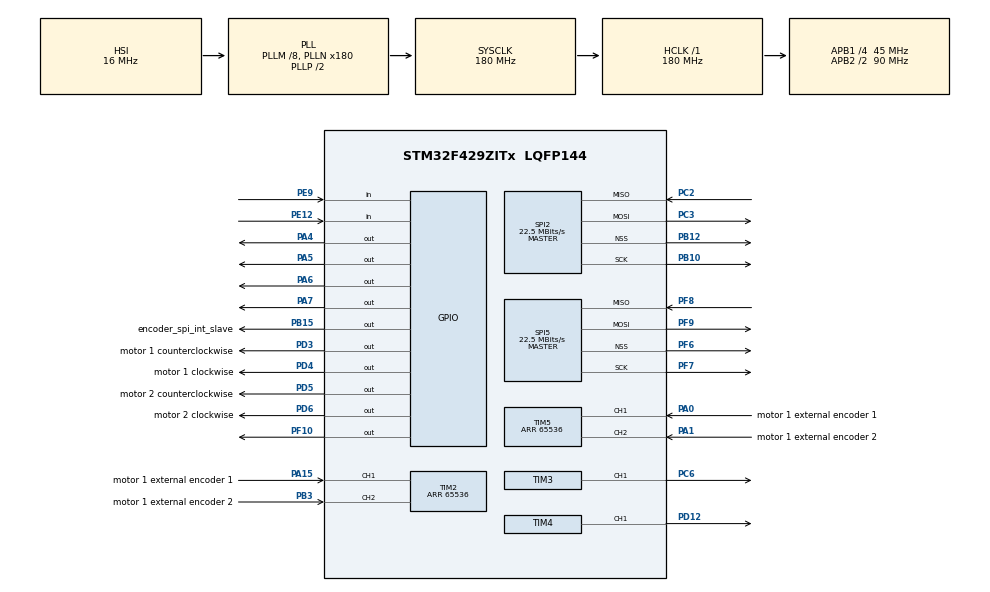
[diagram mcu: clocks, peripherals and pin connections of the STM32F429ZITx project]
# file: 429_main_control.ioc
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Mcu.Family=STM32F4
Mcu.Name=STM32F429ZITx
Mcu.Package=LQFP144
NVIC.PriorityGroup=NVIC_PRIORITYGROUP_3
NVIC.TIM1_BRK_TIM9_IRQn=true\:1\:1\:true\:false\:true\:true
NVIC.TIM1_UP_TIM10_IRQn=true\:0\:0\:false\:false\:true\:true
NVIC.TIM8_UP_TIM13_IRQn=true\:1\:0\:true\:false\:true\:true
PA0/WKUP.GPIO_Label=motor 1 external encoder 1
PA0/WKUP.GPIO_PuPd=GPIO_PULLUP
PA0/WKUP.Signal=S_TIM5_CH1
PA1.GPIO_Label=motor 1 external encoder 2
PA1.GPIO_PuPd=GPIO_PULLUP
PA1.Signal=S_TIM5_CH2
PA15.GPIO_Label=motor 1 external encoder 1
PA15.GPIO_PuPd=GPIO_PULLUP
PA15.Signal=S_TIM2_CH1_ETR
PA4.GPIO_PuPd=GPIO_PULLDOWN
PA4.GPIO_Speed=GPIO_SPEED_FREQ_VERY_HIGH
PA4.PinState=GPIO_PIN_RESET
PA4.Signal=GPIO_Output
PA5.GPIO_PuPd=GPIO_PULLDOWN
PA5.GPIO_Speed=GPIO_SPEED_FREQ_VERY_HIGH
PA5.Signal=GPIO_Output
PA6.GPIO_PuPd=GPIO_PULLDOWN
PA6.GPIO_Speed=GPIO_SPEED_FREQ_VERY_HIGH
PA6.Signal=GPIO_Output
PA7.GPIO_PuPd=GPIO_PULLDOWN
PA7.GPIO_Speed=GPIO_SPEED_FREQ_VERY_HIGH
PA7.Signal=GPIO_Output
PB10.Mode=Full_Duplex_Master
PB10.Signal=SPI2_SCK
PB12.Mode=NSS_Signal_Hard_Output
PB12.Signal=SPI2_NSS
PB15.GPIO_Label=encoder_spi_int_slave
PB15.GPIO_PuPd=GPIO_PULLUP
PB15.GPIO_Speed=GPIO_SPEED_FREQ_VERY_HIGH
PB15.PinState=GPIO_PIN_SET
PB15.Signal=GPIO_Output
PB3.GPIO_Label=motor 1 external encoder 2
PB3.GPIO_PuPd=GPIO_PULLUP
PB3.Signal=S_TIM2_CH2
PC2.Mode=Full_Duplex_Master
PC2.Signal=SPI2_MISO
PC3.Mode=Full_Duplex_Master
PC3.Signal=SPI2_MOSI
PC6.Signal=S_TIM3_CH1
PD12.Signal=S_TIM4_CH1
PD3.GPIO_Label=motor 1 counterclockwise
PD3.GPIO_PuPd=GPIO_PULLDOWN
PD3.GPIO_Speed=GPIO_SPEED_FREQ_VERY_HIGH
PD3.Signal=GPIO_Output
PD4.GPIO_Label=motor 1 clockwise
PD4.GPIO_ModeDefaultOutputPP=GPIO_MODE_OUTPUT_PP
PD4.GPIO_PuPd=GPIO_PULLDOWN
PD4.GPIO_Speed=GPIO_SPEED_FREQ_VERY_HIGH
PD4.Signal=GPIO_Output
PD5.GPIO_Label=motor 2 counterclockwise
PD5.GPIO_PuPd=GPIO_PULLDOWN
PD5.GPIO_Speed=GPIO_SPEED_FREQ_VERY_HIGH
PD5.Signal=GPIO_Output
PD6.GPIO_Label=motor 2 clockwise
PD6.GPIO_PuPd=GPIO_PULLDOWN
PD6.GPIO_Speed=GPIO_SPEED_FREQ_VERY_HIGH
PD6.Signal=GPIO_Output
PE12.GPIO_PuPd=GPIO_PULLUP
PE12.Signal=GPIO_Input
PE9.GPIO_PuPd=GPIO_PULLUP
PE9.Signal=GPIO_Input
PF10.Signal=GPIO_Output
PF6.Mode=NSS_Signal_Hard_Output
PF6.Signal=SPI5_NSS
PF7.Mode=Full_Duplex_Master
PF7.Signal=SPI5_SCK
PF8.Mode=Full_Duplex_Master
PF8.Signal=SPI5_MISO
PF9.Mode=Full_Duplex_Master
PF9.Signal=SPI5_MOSI
PH0/OSC_IN.Mode=HSE-External-Oscillator
PH0/OSC_IN.Signal=RCC_OSC_IN
PH1/OSC_OUT.Mode=HSE-External-Oscillator
PH1/OSC_OUT.Signal=RCC_OSC_OUT
ProjectManager.HeapSize=0x200
ProjectManager.StackSize=0x400
ProjectManager.TargetToolchain=MDK-ARM V5
RCC.48MHZClocksFreq_Value=90000000
RCC.AHBFreq_Value=180000000
RCC.APB1CLKDivider=RCC_HCLK_DIV4
RCC.APB1Freq_Value=45000000
RCC.APB1TimFreq_Value=90000000
RCC.APB2CLKDivider=RCC_HCLK_DIV2
RCC.APB2Freq_Value=90000000
RCC.APB2TimFreq_Value=180000000
RCC.CortexFreq_Value=180000000
RCC.HCLKFreq_Value=180000000
RCC.HSE_VALUE=8000000
RCC.HSI_VALUE=16000000
RCC.LSE_VALUE=32768
RCC.PLLM=8
RCC.PLLN=180
RCC.SYSCLKFreq_VALUE=180000000
RCC.SYSCLKSource=RCC_SYSCLKSOURCE_PLLCLK
RCC.VCOOutputFreq_Value=360000000
SH.S_TIM2_CH1_ETR.0=TIM2_CH1,Encoder_Interface
SH.S_TIM2_CH2.0=TIM2_CH2,Encoder_Interface
SH.S_TIM3_CH1.0=TIM3_CH1,PWM Generation1 CH1
SH.S_TIM4_CH1.0=TIM4_CH1,PWM Generation1 CH1
SH.S_TIM5_CH1.0=TIM5_CH1,Encoder_Interface
SH.S_TIM5_CH2.0=TIM5_CH2,Encoder_Interface
SPI2.BaudRatePrescaler=SPI_BAUDRATEPRESCALER_2
SPI2.CalculateBaudRate=22.5 MBits/s
SPI2.Direction=SPI_DIRECTION_2LINES
SPI2.Mode=SPI_MODE_MASTER
SPI2.VirtualNSS=VM_NSSHARD
SPI2.VirtualType=VM_MASTER
SPI5.BaudRatePrescaler=SPI_BAUDRATEPRESCALER_4
SPI5.CalculateBaudRate=22.5 MBits/s
SPI5.Direction=SPI_DIRECTION_2LINES
SPI5.Mode=SPI_MODE_MASTER
SPI5.VirtualNSS=VM_NSSHARD
SPI5.VirtualType=VM_MASTER
TIM1.Period=1
TIM1.Prescaler=180-1
TIM2.EncoderMode=TIM_ENCODERMODE_TI12
TIM2.IC1Filter=5
TIM2.IC2Filter=5
TIM2.Period=65536
TIM2.TIM_MasterOutputTrigger=TIM_TRGO_UPDATE
TIM3.Channel-PWM\ Generation1\ CH1=TIM_CHANNEL_1
TIM3.Period=9000-1
TIM3.Prescaler=0
TIM4.Channel-PWM\ Generation1\ CH1=TIM_CHANNEL_1
TIM4.Period=9000-1
TIM4.Prescaler=0
TIM5.EncoderMode=TIM_ENCODERMODE_TI12
TIM5.IC1Filter=5
TIM5.IC2Filter=5
TIM5.Period=65536
TIM5.TIM_MasterOutputTrigger=TIM_TRGO_UPDATE
TIM8.Period=1000-1
TIM8.Prescaler=1800-1
TIM9.Period=1000-1
TIM9.Prescaler=180-1
VP_CRC_VS_CRC.Mode=CRC_Activate
VP_TIM1_VS_ClockSourceINT.Mode=Internal
VP_TIM8_VS_ClockSourceINT.Mode=Internal
VP_TIM9_VS_ClockSourceINT.Mode=Internal
board=429_main_control

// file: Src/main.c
/* USER CODE BEGIN Header */
/**
  ******************************************************************************
  * @file           : main.c
  * @brief          : Main program body
  ******************************************************************************
  ** This notice applies to any and all portions of this file
  * that are not between comment pairs USER CODE BEGIN and
  * USER CODE END. Other portions of this file, whether
  * inserted by the user or by software development tools
  * are owned by their respective copyright owners.
  *
  * COPYRIGHT(c) 2019 STMicroelectronics
  *
  * Redistribution and use in source and binary forms, with or without modification,
  * are permitted provided that the following conditions are met:
  *   1. Redistributions of source code must retain the above copyright notice,
  *      this list of conditions and the following disclaimer.
  *   2. Redistributions in binary form must reproduce the above copyright notice,
  *      this list of conditions and the following disclaimer in the documentation
  *      and/or other materials provided with the distribution.
  *   3. Neither the name of STMicroelectronics nor the names of its contributors
  *      may be used to endorse or promote products derived from this software
  *      without specific prior written permission.
  *
  * THIS SOFTWARE IS PROVIDED BY THE COPYRIGHT HOLDERS AND CONTRIBUTORS "AS IS"
  * AND ANY EXPRESS OR IMPLIED WARRANTIES, INCLUDING, BUT NOT LIMITED TO, THE
  * IMPLIED WARRANTIES OF MERCHANTABILITY AND FITNESS FOR A PARTICULAR PURPOSE ARE
  * DISCLAIMED. IN NO EVENT SHALL THE COPYRIGHT HOLDER OR CONTRIBUTORS BE LIABLE
  * FOR ANY DIRECT, INDIRECT, INCIDENTAL, SPECIAL, EXEMPLARY, OR CONSEQUENTIAL
  * DAMAGES (INCLUDING, BUT NOT LIMITED TO, PROCUREMENT OF SUBSTITUTE GOODS OR
  * SERVICES; LOSS OF USE, DATA, OR PROFITS; OR BUSINESS INTERRUPTION) HOWEVER
  * CAUSED AND ON ANY THEORY OF LIABILITY, WHETHER IN CONTRACT, STRICT LIABILITY,
  * OR TORT (INCLUDING NEGLIGENCE OR OTHERWISE) ARISING IN ANY WAY OUT OF THE USE
  * OF THIS SOFTWARE, EVEN IF ADVISED OF THE POSSIBILITY OF SUCH DAMAGE.
  *
  ******************************************************************************
  */
/* USER CODE END Header */

#include "main.h"
#include "crc.h"
#include "spi.h"
#include "tim.h"
#include "gpio.h"

/* USER CODE BEGIN Includes */
#include "..\MDK-ARM\robot.h"
//#include "..\MDK-ARM\script.h"

/* USER CODE END Includes */

/* USER CODE BEGIN PV */
/* Private variables ---------------------------------------------------------*/
struct ROBOT eurobot2019;
int p = 0;
volatile double X=0, Y=0, Theta=0;

/* USER CODE END PV */

void SystemClock_Config(void);
/* USER CODE BEGIN PFP */
/* Private function prototypes -----------------------------------------------*/

/* USER CODE END PFP */

int main(void)
{

  /* MCU Configuration--------------------------------------------------------*/

  /* Reset of all peripherals, Initializes the Flash interface and the Systick. */
  HAL_Init();

  /* Configure the system clock */
  SystemClock_Config();

  /* Initialize all configured peripherals */
  MX_GPIO_Init();
  MX_SPI2_Init();
  MX_TIM1_Init();
  MX_TIM2_Init();
  MX_TIM5_Init();
  MX_TIM3_Init();
  MX_TIM4_Init();
  MX_TIM9_Init();
  MX_TIM8_Init();
  MX_CRC_Init();
  MX_SPI5_Init();
  /* USER CODE BEGIN 2 */

	Hardware_Init(&eurobot2019.hardware);
	ControlSystem_Init(&eurobot2019.controlsystem);

	HAL_TIM_Base_Start_IT(&htim8);
	HAL_TIM_Base_Start_IT(&htim9);

	//Set_Command_Point(&eurobot2019.controlsystem.position, 0, 0, 0);
	eurobot2019.NavigateComplete = 0;

  /* USER CODE END 2 */

  /* Infinite loop */
  /* USER CODE BEGIN WHILE */
  while (1)
  {
		/*
		X = test[p].X;
		Y = test[p].Y;
		Theta = test[p].Theta;
		HAL_Delay(200);
		if(eurobot2019.NavigateComplete){
			eurobot2019.NavigateComplete = 0;
			p ++;
			if(p >= 5) break;
		}
		*/

    /* USER CODE END WHILE */

  }
}

void SystemClock_Config(void)
{
  RCC_OscInitTypeDef RCC_OscInitStruct = {0};
  RCC_ClkInitTypeDef RCC_ClkInitStruct = {0};

  /**Configure the main internal regulator output voltage
  */
  __HAL_RCC_PWR_CLK_ENABLE();
  __HAL_PWR_VOLTAGESCALING_CONFIG(PWR_REGULATOR_VOLTAGE_SCALE1);
  /**Initializes the CPU, AHB and APB busses clocks
  */
  RCC_OscInitStruct.OscillatorType = RCC_OSCILLATORTYPE_HSI;
  RCC_OscInitStruct.HSIState = RCC_HSI_ON;
  RCC_OscInitStruct.HSICalibrationValue = RCC_HSICALIBRATION_DEFAULT;
  RCC_OscInitStruct.PLL.PLLState = RCC_PLL_ON;
  RCC_OscInitStruct.PLL.PLLSource = RCC_PLLSOURCE_HSI;
  RCC_OscInitStruct.PLL.PLLM = 8;
  RCC_OscInitStruct.PLL.PLLN = 180;
  RCC_OscInitStruct.PLL.PLLP = RCC_PLLP_DIV2;
  RCC_OscInitStruct.PLL.PLLQ = 4;
  if (HAL_RCC_OscConfig(&RCC_OscInitStruct) != HAL_OK)
  {
    Error_Handler();
  }
  /**Activate the Over-Drive mode
  */
  if (HAL_PWREx_EnableOverDrive() != HAL_OK)
  {
    Error_Handler();
  }
  /**Initializes the CPU, AHB and APB busses clocks
  */
  RCC_ClkInitStruct.ClockType = RCC_CLOCKTYPE_HCLK|RCC_CLOCKTYPE_SYSCLK
                              |RCC_CLOCKTYPE_PCLK1|RCC_CLOCKTYPE_PCLK2;
  RCC_ClkInitStruct.SYSCLKSource = RCC_SYSCLKSOURCE_PLLCLK;
  RCC_ClkInitStruct.AHBCLKDivider = RCC_SYSCLK_DIV1;
  RCC_ClkInitStruct.APB1CLKDivider = RCC_HCLK_DIV4;
  RCC_ClkInitStruct.APB2CLKDivider = RCC_HCLK_DIV2;

  if (HAL_RCC_ClockConfig(&RCC_ClkInitStruct, FLASH_LATENCY_5) != HAL_OK)
  {
    Error_Handler();
  }
}

void Error_Handler(void)
{
  while(1)
  {
  }
}

/************************ (C) COPYRIGHT STMicroelectronics *****END OF FILE****/
